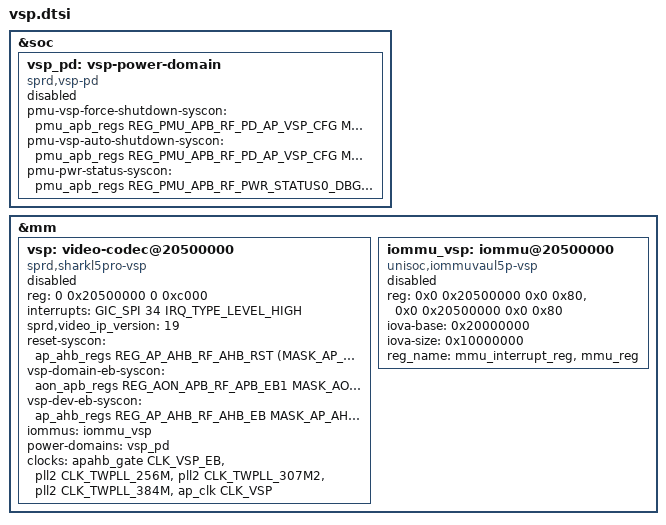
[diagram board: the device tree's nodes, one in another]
// SPDX-License-Identifier: GPL-2.0-only
/*
 * Unisoc VSP SoC dts file
 *
 * Copyright (C) 2021, Unisoc Inc.
 */

&soc {

	vsp_pd: vsp-power-domain {
		compatible = "sprd,vsp-pd";
		pmu-vsp-force-shutdown-syscon = <&pmu_apb_regs
			REG_PMU_APB_RF_PD_AP_VSP_CFG
			MASK_PMU_APB_RF_PD_AP_VSP_FORCE_SHUTDOWN>;
			pmu-vsp-auto-shutdown-syscon = <&pmu_apb_regs
			REG_PMU_APB_RF_PD_AP_VSP_CFG
			MASK_PMU_APB_RF_PD_AP_VSP_AUTO_SHUTDOWN_EN>;
		pmu-pwr-status-syscon = <&pmu_apb_regs
			REG_PMU_APB_RF_PWR_STATUS0_DBG
			MASK_PMU_APB_RF_PD_AP_VSP_STATE>;
		#power-domain-cells = <0>;
		status = "disabled";
	};
};

&mm {
	vsp: video-codec@20500000 {
		compatible = "sprd,sharkl5pro-vsp";
		reg = <0 0x20500000 0 0xc000>;
		interrupts = <GIC_SPI 34 IRQ_TYPE_LEVEL_HIGH>;
		sprd,video_ip_version = <19>;
		reset-syscon = <&ap_ahb_regs
			REG_AP_AHB_RF_AHB_RST
			(MASK_AP_AHB_RF_VSP_SOFT_RST |
			MASK_AP_AHB_RF_VSP_GLOBAL_SOFT_RST)>;
		vsp-domain-eb-syscon = <&aon_apb_regs
			REG_AON_APB_RF_APB_EB1
			MASK_AON_APB_RF_AP_SYST_EB>;
		vsp-dev-eb-syscon = <&ap_ahb_regs
			REG_AP_AHB_RF_AHB_EB
			MASK_AP_AHB_RF_VSP_EB>;
		iommus = <&iommu_vsp>;
		power-domains = <&vsp_pd>;
		status = "disabled";
		clock-names = "clk_ahb_gate_vsp_eb",
			"clk_src_256m",
			"clk_src_307m2",
			"clk_src_384m",
			"clk_vsp";
		clocks = <&apahb_gate CLK_VSP_EB>,
			<&pll2 CLK_TWPLL_256M>,
			<&pll2 CLK_TWPLL_307M2>,
			<&pll2 CLK_TWPLL_384M>,
			<&ap_clk CLK_VSP>;

	};

	iommu_vsp: iommu@20500000 {
		compatible = "unisoc,iommuvaul5p-vsp";
		reg = <0x0 0x20500000 0x0 0x80>,
		      <0x0 0x20500000 0x0 0x80>;
		iova-base = <0x20000000>;
		iova-size = <0x10000000>;
		reg_name = "mmu_interrupt_reg","mmu_reg";
		status = "disabled";
		#iommu-cells = <0>;

	};
};

